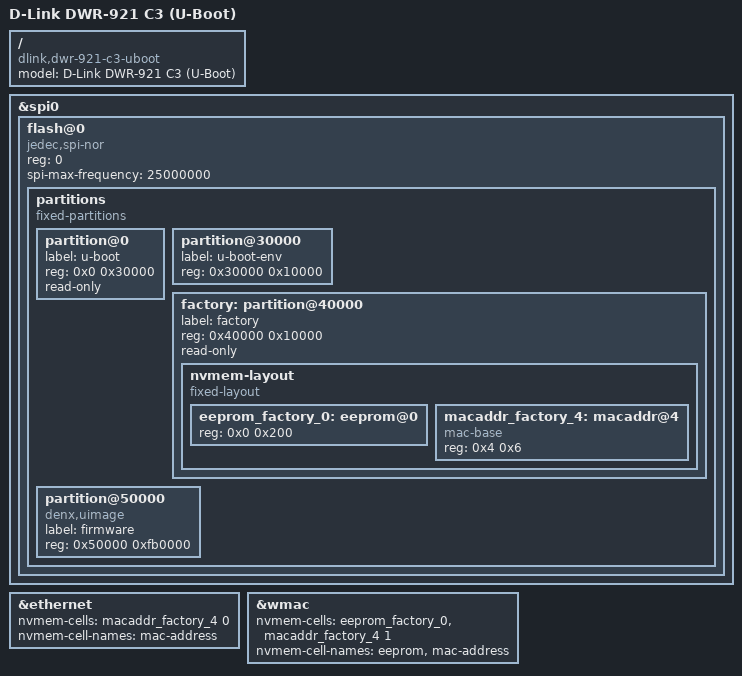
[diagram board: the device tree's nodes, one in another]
// SPDX-License-Identifier: GPL-2.0-or-later OR MIT

#include "mt7620n_dlink_dwr-921.dtsi"

/ {
	compatible = "dlink,dwr-921-c3-uboot", "ralink,mt7620n-soc";
	model = "D-Link DWR-921 C3 (U-Boot)";
};

&spi0 {
	status = "okay";

	flash@0 {
		compatible = "jedec,spi-nor";
		reg = <0>;
		spi-max-frequency = <25000000>;

		partitions {
			compatible = "fixed-partitions";
			#address-cells = <1>;
			#size-cells = <1>;

			partition@0 {
				label = "u-boot";
				reg = <0x0 0x30000>;
				read-only;
			};

			partition@30000 {
				label = "u-boot-env";
				reg = <0x30000 0x10000>;
			};

			factory: partition@40000 {
				label = "factory";
				reg = <0x40000 0x10000>;
				read-only;

				nvmem-layout {
					compatible = "fixed-layout";
					#address-cells = <1>;
					#size-cells = <1>;

					eeprom_factory_0: eeprom@0 {
						reg = <0x0 0x200>;
					};

					macaddr_factory_4: macaddr@4 {
						compatible = "mac-base";
						reg = <0x4 0x6>;
						#nvmem-cell-cells = <1>;
					};
				};
			};

			partition@50000 {
				compatible = "denx,uimage";
				label = "firmware";
				reg = <0x50000 0xfb0000>;
			};
		};
	};
};

&ethernet {
	nvmem-cells = <&macaddr_factory_4 0>;
	nvmem-cell-names = "mac-address";
};

&wmac {
	nvmem-cells = <&eeprom_factory_0>, <&macaddr_factory_4 1>;
	nvmem-cell-names = "eeprom", "mac-address";
};
